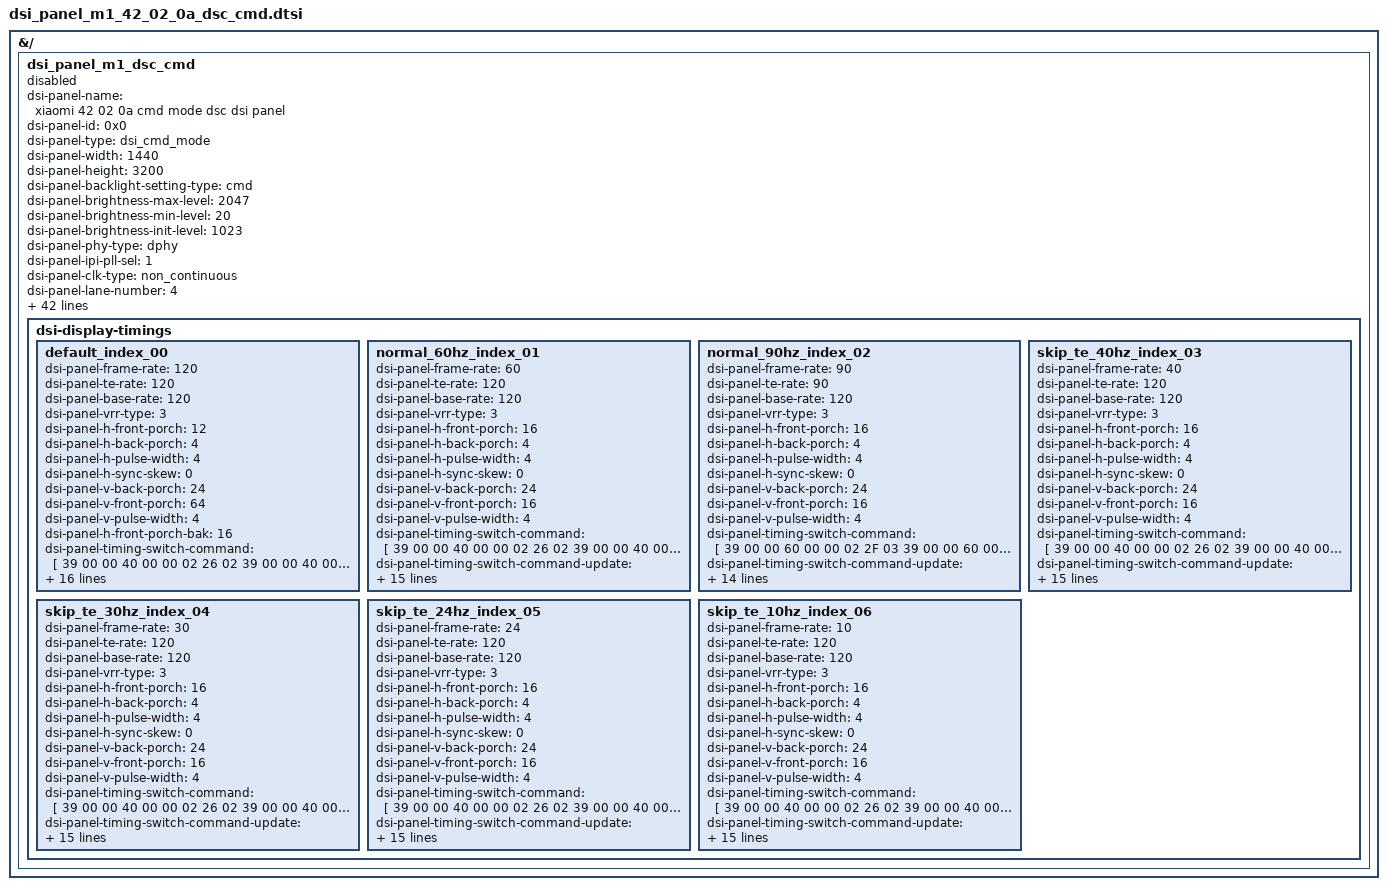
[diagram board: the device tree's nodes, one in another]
// SPDX-License-Identifier: GPL-2.0+
/*
 * DSI panel device tree for fpga testing
 *
 * (C) Copyright 2023 - 2024, X-Ring, Inc.
 */

&{/} {
	dsi_panel_m1_dsc_cmd: dsi_panel_m1_dsc_cmd {
		status = "disabled";
		dsi-panel-name = "xiaomi 42 02 0a cmd mode dsc dsi panel";
		dsi-panel-id = <0x0>;
		dsi-panel-type = "dsi_cmd_mode";
		dsi-panel-width = <1440>;
		dsi-panel-height = <3200>;
		dsi-panel-backlight-setting-type = "cmd";
		dsi-panel-brightness-max-level = <2047>;
		dsi-panel-brightness-min-level = <20>;
		dsi-panel-brightness-init-level = <1023>;
		dsi-panel-phy-type = "dphy";
		dsi-panel-ipi-pll-sel = <1>; // 0:phy pll 1:dpu pll
		dsi-panel-clk-type = "non_continuous";
		dsi-panel-lane-number = <4>;
		dsi-panel-lane-rate = <1360000000>;
		dsi-panel-pixel-clock = <26154000>;
		dsi-panel-lane-rate-bak = <1380924237>;
		dsi-panel-pixel-clock-bak = <26556235>;
		dsi-panel-bpp = <30>;
		dsi-panel-virtual-channel = <0>;
		dsi-panel-bta-enable;
		dsi-panel-eotp-enable;
		dsi-panel-hdr-enabled;
		dsi-panel-peak-brightness = <4200000>;
		dsi-panel-blackness-level = <3230>;
		dsi-panel-physical-width-dimension = <701>;
		dsi-panel-physical-height-dimension = <1558>;
		dsi-panel-physical-type = "ltpo";
		dsi-panel-te-sel = /bits/ 8 <0x0>;
		dsi-panel-port-mask = /bits/ 8 <0x1>; // DSI-0: 0001
		dsi-panel-boot-up-profile = <1>; //profile_1
		dsi-panel-lowpower-ctrl = <0x3fd>; //support frame power ctrl
		dsi-panel-frame-power-mask = <0x6>;
		dsi-panel-frame-power-max-refresh-rate = <30>;
		dsi-panel-hw-ulps-max-refresh-rate = <30>;
		dsi-panel-idle-policy = <0x0>;
		dsi-panel-dsc-compression-mode = "dsc";
		dsi-panel-dsc-version = <0x12>;
		dsi-panel-dsc-scr-version = <0>;
		dsi-panel-dsc-pic-height = <3200>;
		dsi-panel-dsc-pic-width = <1440>;
		dsi-panel-dsc-slice-height = <20>;
		dsi-panel-dsc-slice-width = <720>;
		dsi-panel-dsc-bpc = /bits/ 8 <10>;
		dsi-panel-dsc-bpp = /bits/ 8 <8>;
		dsi-panel-dsc-pps-table = [
			12 00 00 AB 30 80 0C 80 05 A0 00 14 02 D0 02 D0
			02 00 02 86 00 20 02 15 00 0A 00 0D 05 7A 03 D1
			18 00 10 F0 07 10 20 00 06 0F 0F 33 0E 1C 2A 38
			46 54 62 69 70 77 79 7B 7D 7E 02 02 22 00 2A 40
			2A BE 3A FC 3A FA 3A F8 3B 38 3B 78 43 B6 4B B6
			4B F6 4B F4 64 34 84 74 00 00 00 00 00 00 00 00
			00 00 00 00 00 00 00 00 00 00 00 00 00 00 00 00
			00 00 00 00 00 00 00 00 00 00 00 00 00 00 00 00
		];
		dsi-panel-vrr-enable;
		dsi-panel-reset-after-lp11;
		dsi-panel-esd-check-enable;
		dsi-panel-esd-mode = "err_int";
		dsi-panel-status-command = [06 01 00 01 00 00 01 91];
		dsi-panel-status-command-state = "dsi_hs_mode";
		dsi-panel-status-value = <0xAB 0xA8>;
		dsi-panel-status-length = <2>;
		dsi-display-timings {
			default_index_00 {
				dsi-panel-frame-rate = <120>;
				dsi-panel-te-rate = <120>;
				dsi-panel-base-rate = <120>;
				dsi-panel-vrr-type = <3>;
				dsi-panel-h-front-porch = <12>;
				dsi-panel-h-back-porch = <4>;
				dsi-panel-h-pulse-width = <4>;
				dsi-panel-h-sync-skew = <0>;
				dsi-panel-v-back-porch = <24>;
				dsi-panel-v-front-porch = <64>;
				dsi-panel-v-pulse-width = <4>;
				dsi-panel-h-front-porch-bak = <16>;

				dsi-panel-timing-switch-command = [
					/* 120Hz */
					39 00 00 40 00 00 02 26 02
					39 00 00 40 00 00 02 2F 02
					39 00 00 40 00 00 06 F0 55 AA 52 08 00
					39 00 00 40 00 00 02 BC 00
					39 00 00 00 00 00 02 2C 00
				];
				dsi-panel-timing-switch-command-update = <0x26 0 1>, <0x2F 1 1>;
				dsi-panel-timing-switch-command-state = "dsi_hs_mode";
				dsi-panel-flat-mode-gamma-cfg = <0x26 0x00 0x02>, <0x2F 0x00 0x02>;

				dsi-panel-on-command = [
					#include "dsi_panel_m1_42_02_0a_dsc_cmd_dsi_on_common.dtsi"
					/* 120Hz */
					39 00 00 40 00 00 02 26 02
					39 00 00 40 00 00 02 2F 02
					39 00 00 40 00 00 06 F0 55 AA 52 08 00
					39 00 00 40 00 00 02 BC 00
					39 00 00 40 00 00 02 2C 00
					/* Sleep Out */
					05 00 00 00 78 00 01 11
					39 00 00 40 00 00 06 F0 55 AA 52 08 02
					39 00 00 40 00 00 02 CC 10
					/* Display On */
					05 00 00 00 00 00 01 29
				];
				dsi-panel-on-command-state = "dsi_hs_mode";

				dsi-panel-off-command = [
					/*AOD Off*/
					39 00 00 40 00 00 02 65 00
					39 00 00 40 00 00 02 38 00
					39 00 00 00 32 00 02 2C 00
					/*Power off*/
					05 00 00 00 00 00 01 28
					05 00 00 00 78 00 01 10
				];
				dsi-panel-off-command-state = "dsi_hs_mode";

				dsi-panel-backlight-command = [
					39 00 00 00 00 00 03 51 03 FF
				];
				dsi-panel-backlight-command-update = <0x51 0 2>;
				dsi-panel-backlight-command-state = "dsi_hs_mode";
			};
			normal_60hz_index_01 {
				dsi-panel-frame-rate = <60>;
				dsi-panel-te-rate = <120>;
				dsi-panel-base-rate = <120>;
				dsi-panel-vrr-type = <3>;
				dsi-panel-h-front-porch = <16>;
				dsi-panel-h-back-porch = <4>;
				dsi-panel-h-pulse-width = <4>;
				dsi-panel-h-sync-skew = <0>;
				dsi-panel-v-back-porch = <24>;
				dsi-panel-v-front-porch = <16>;
				dsi-panel-v-pulse-width = <4>;

				dsi-panel-timing-switch-command = [
					/* 120Hz */
					39 00 00 40 00 00 02 26 02
					39 00 00 40 00 00 02 2F 02
					39 00 00 40 00 00 06 F0 55 AA 52 08 00
					39 00 00 40 00 00 02 BC 00
					39 00 00 00 00 00 02 2C 00
				];
				dsi-panel-timing-switch-command-update = <0x26 0 1>, <0x2F 1 1>;
				dsi-panel-timing-switch-command-state = "dsi_hs_mode";
				dsi-panel-flat-mode-gamma-cfg = <0x26 0x00 0x02>, <0x2F 0x00 0x02>;

				dsi-panel-on-command = [
					#include "dsi_panel_m1_42_02_0a_dsc_cmd_dsi_on_common.dtsi"
					/* 120Hz */
					39 00 00 40 00 00 02 26 02
					39 00 00 40 00 00 02 2F 02
					39 00 00 40 00 00 06 F0 55 AA 52 08 00
					39 00 00 40 00 00 02 BC 00
					39 00 00 40 00 00 02 2C 00
					/* Sleep Out */
					05 00 00 00 78 00 01 11
					39 00 00 40 00 00 06 F0 55 AA 52 08 02
					39 00 00 40 00 00 02 CC 10
					/* Display On */
					05 00 00 00 00 00 01 29
				];
				dsi-panel-on-command-state = "dsi_hs_mode";

				dsi-panel-off-command = [
					/*AOD Off*/
					39 00 00 40 00 00 02 65 00
					39 00 00 40 00 00 02 38 00
					39 00 00 00 32 00 02 2C 00
					/*Power off*/
					05 00 00 00 00 00 01 28
					05 00 00 00 78 00 01 10
				];
				dsi-panel-off-command-state = "dsi_hs_mode";

				dsi-panel-backlight-command = [
					39 00 00 00 00 00 03 51 03 FF
				];
				dsi-panel-backlight-command-update = <0x51 0 2>;
				dsi-panel-backlight-command-state = "dsi_hs_mode";
			};
			normal_90hz_index_02 {
				dsi-panel-frame-rate = <90>;
				dsi-panel-te-rate = <90>;
				dsi-panel-base-rate = <120>;
				dsi-panel-vrr-type = <3>;
				dsi-panel-h-front-porch = <16>;
				dsi-panel-h-back-porch = <4>;
				dsi-panel-h-pulse-width = <4>;
				dsi-panel-h-sync-skew = <0>;
				dsi-panel-v-back-porch = <24>;
				dsi-panel-v-front-porch = <16>;
				dsi-panel-v-pulse-width = <4>;

				dsi-panel-timing-switch-command = [
					39 00 00 60 00 00 02 2F 03
					39 00 00 60 00 00 06 F0 55 AA 52 08 00
					39 00 00 20 00 00 02 BC 00
				];
				dsi-panel-timing-switch-command-update = <0x2F 0 1>;
				dsi-panel-timing-switch-command-state = "dsi_hs_mode";
				dsi-panel-flat-mode-gamma-cfg = <0x2F 0x01 0x03>;

				dsi-panel-on-command = [
					#include "dsi_panel_m1_42_02_0a_dsc_cmd_dsi_on_common.dtsi"
					/* 90HZ */
					39 00 00 40 00 00 02 2F 03
					39 00 00 40 00 00 06 F0 55 AA 52 08 00
					39 00 00 40 00 00 02 BC 00
					/* Sleep Out */
					05 00 00 00 78 00 01 11
					39 00 00 40 00 00 06 F0 55 AA 52 08 02
					39 00 00 40 00 00 02 CC 10
					/* Display On */
					05 00 00 00 00 00 01 29
				];
				dsi-panel-on-command-state = "dsi_hs_mode";

				dsi-panel-off-command = [
					/*AOD Off*/
					39 00 00 40 00 00 02 65 00
					39 00 00 40 00 00 02 38 00
					39 00 00 00 32 00 02 2C 00
					/*Power off*/
					05 00 00 00 00 00 01 28
					05 00 00 00 78 00 01 10
				];
				dsi-panel-off-command-state = "dsi_hs_mode";

				dsi-panel-backlight-command = [
					39 00 00 00 00 00 03 51 03 FF
				];
				dsi-panel-backlight-command-update = <0x51 0 2>;
				dsi-panel-backlight-command-state = "dsi_hs_mode";
			};
			skip_te_40hz_index_03 {
				dsi-panel-frame-rate = <40>;
				dsi-panel-te-rate = <120>;
				dsi-panel-base-rate = <120>;
				dsi-panel-vrr-type = <3>;
				dsi-panel-h-front-porch = <16>;
				dsi-panel-h-back-porch = <4>;
				dsi-panel-h-pulse-width = <4>;
				dsi-panel-h-sync-skew = <0>;
				dsi-panel-v-back-porch = <24>;
				dsi-panel-v-front-porch = <16>;
				dsi-panel-v-pulse-width = <4>;

				dsi-panel-timing-switch-command = [
					/* 120Hz */
					39 00 00 40 00 00 02 26 02
					39 00 00 40 00 00 02 2F 02
					39 00 00 40 00 00 06 F0 55 AA 52 08 00
					39 00 00 40 00 00 02 BC 00
					39 00 00 00 00 00 02 2C 00
				];
				dsi-panel-timing-switch-command-update = <0x26 0 1>, <0x2F 1 1>;
				dsi-panel-timing-switch-command-state = "dsi_hs_mode";
				dsi-panel-flat-mode-gamma-cfg = <0x26 0x00 0x02>, <0x2F 0x00 0x02>;

				dsi-panel-on-command = [
					#include "dsi_panel_m1_42_02_0a_dsc_cmd_dsi_on_common.dtsi"
					/* 120Hz */
					39 00 00 40 00 00 02 26 02
					39 00 00 40 00 00 02 2F 02
					39 00 00 40 00 00 06 F0 55 AA 52 08 00
					39 00 00 40 00 00 02 BC 00
					39 00 00 40 00 00 02 2C 00
					/* Sleep Out */
					05 00 00 00 78 00 01 11
					39 00 00 40 00 00 06 F0 55 AA 52 08 02
					39 00 00 40 00 00 02 CC 10
					/* Display On */
					05 00 00 00 00 00 01 29
				];
				dsi-panel-on-command-state = "dsi_hs_mode";

				dsi-panel-off-command = [
					/*AOD Off*/
					39 00 00 40 00 00 02 65 00
					39 00 00 40 00 00 02 38 00
					39 00 00 00 32 00 02 2C 00
					/*Power off*/
					05 00 00 00 00 00 01 28
					05 00 00 00 78 00 01 10
				];
				dsi-panel-off-command-state = "dsi_hs_mode";

				dsi-panel-backlight-command = [
					39 00 00 00 00 00 03 51 03 FF
				];
				dsi-panel-backlight-command-update = <0x51 0 2>;
				dsi-panel-backlight-command-state = "dsi_hs_mode";
			};
			skip_te_30hz_index_04 {
				dsi-panel-frame-rate = <30>;
				dsi-panel-te-rate = <120>;
				dsi-panel-base-rate = <120>;
				dsi-panel-vrr-type = <3>;
				dsi-panel-h-front-porch = <16>;
				dsi-panel-h-back-porch = <4>;
				dsi-panel-h-pulse-width = <4>;
				dsi-panel-h-sync-skew = <0>;
				dsi-panel-v-back-porch = <24>;
				dsi-panel-v-front-porch = <16>;
				dsi-panel-v-pulse-width = <4>;

				dsi-panel-timing-switch-command = [
					/* 120Hz */
					39 00 00 40 00 00 02 26 02
					39 00 00 40 00 00 02 2F 02
					39 00 00 40 00 00 06 F0 55 AA 52 08 00
					39 00 00 40 00 00 02 BC 00
					39 00 00 00 00 00 02 2C 00
				];
				dsi-panel-timing-switch-command-update = <0x26 0 1>, <0x2F 1 1>;
				dsi-panel-timing-switch-command-state = "dsi_hs_mode";
				dsi-panel-flat-mode-gamma-cfg = <0x26 0x00 0x02>, <0x2F 0x00 0x02>;

				dsi-panel-on-command = [
					#include "dsi_panel_m1_42_02_0a_dsc_cmd_dsi_on_common.dtsi"
					/* 120Hz */
					39 00 00 40 00 00 02 26 02
					39 00 00 40 00 00 02 2F 02
					39 00 00 40 00 00 06 F0 55 AA 52 08 00
					39 00 00 40 00 00 02 BC 00
					39 00 00 40 00 00 02 2C 00
					/* Sleep Out */
					05 00 00 00 78 00 01 11
					39 00 00 40 00 00 06 F0 55 AA 52 08 02
					39 00 00 40 00 00 02 CC 10
					/* Display On */
					05 00 00 00 00 00 01 29
				];
				dsi-panel-on-command-state = "dsi_hs_mode";

				dsi-panel-off-command = [
					/*AOD Off*/
					39 00 00 40 00 00 02 65 00
					39 00 00 40 00 00 02 38 00
					39 00 00 00 32 00 02 2C 00
					/*Power off*/
					05 00 00 00 00 00 01 28
					05 00 00 00 78 00 01 10
				];
				dsi-panel-off-command-state = "dsi_hs_mode";

				dsi-panel-backlight-command = [
					39 00 00 00 00 00 03 51 03 FF
				];
				dsi-panel-backlight-command-update = <0x51 0 2>;
				dsi-panel-backlight-command-state = "dsi_hs_mode";
			};
			skip_te_24hz_index_05 {
				dsi-panel-frame-rate = <24>;
				dsi-panel-te-rate = <120>;
				dsi-panel-base-rate = <120>;
				dsi-panel-vrr-type = <3>;
				dsi-panel-h-front-porch = <16>;
				dsi-panel-h-back-porch = <4>;
				dsi-panel-h-pulse-width = <4>;
				dsi-panel-h-sync-skew = <0>;
				dsi-panel-v-back-porch = <24>;
				dsi-panel-v-front-porch = <16>;
				dsi-panel-v-pulse-width = <4>;

				dsi-panel-timing-switch-command = [
					/* 120Hz */
					39 00 00 40 00 00 02 26 02
					39 00 00 40 00 00 02 2F 02
					39 00 00 40 00 00 06 F0 55 AA 52 08 00
					39 00 00 40 00 00 02 BC 00
					39 00 00 00 00 00 02 2C 00
				];
				dsi-panel-timing-switch-command-update = <0x26 0 1>, <0x2F 1 1>;
				dsi-panel-timing-switch-command-state = "dsi_hs_mode";
				dsi-panel-flat-mode-gamma-cfg = <0x26 0x00 0x02>, <0x2F 0x00 0x02>;

				dsi-panel-on-command = [
					#include "dsi_panel_m1_42_02_0a_dsc_cmd_dsi_on_common.dtsi"
					/* 120Hz */
					39 00 00 40 00 00 02 26 02
					39 00 00 40 00 00 02 2F 02
					39 00 00 40 00 00 06 F0 55 AA 52 08 00
					39 00 00 40 00 00 02 BC 00
					39 00 00 40 00 00 02 2C 00
					/* Sleep Out */
					05 00 00 00 78 00 01 11
					39 00 00 40 00 00 06 F0 55 AA 52 08 02
					39 00 00 40 00 00 02 CC 10
					/* Display On */
					05 00 00 00 00 00 01 29
				];
				dsi-panel-on-command-state = "dsi_hs_mode";

				dsi-panel-off-command = [
					/*AOD Off*/
					39 00 00 40 00 00 02 65 00
					39 00 00 40 00 00 02 38 00
					39 00 00 00 32 00 02 2C 00
					/*Power off*/
					05 00 00 00 00 00 01 28
					05 00 00 00 78 00 01 10
				];
				dsi-panel-off-command-state = "dsi_hs_mode";

				dsi-panel-backlight-command = [
					39 00 00 00 00 00 03 51 03 FF
				];
				dsi-panel-backlight-command-update = <0x51 0 2>;
				dsi-panel-backlight-command-state = "dsi_hs_mode";
			};
			skip_te_10hz_index_06 {
				dsi-panel-frame-rate = <10>;
				dsi-panel-te-rate = <120>;
				dsi-panel-base-rate = <120>;
				dsi-panel-vrr-type = <3>;
				dsi-panel-h-front-porch = <16>;
				dsi-panel-h-back-porch = <4>;
				dsi-panel-h-pulse-width = <4>;
				dsi-panel-h-sync-skew = <0>;
				dsi-panel-v-back-porch = <24>;
				dsi-panel-v-front-porch = <16>;
				dsi-panel-v-pulse-width = <4>;

				dsi-panel-timing-switch-command = [
					/* 120Hz */
					39 00 00 40 00 00 02 26 02
					39 00 00 40 00 00 02 2F 02
					39 00 00 40 00 00 06 F0 55 AA 52 08 00
					39 00 00 40 00 00 02 BC 00
					39 00 00 00 00 00 02 2C 00
				];
				dsi-panel-timing-switch-command-update = <0x26 0 1>, <0x2F 1 1>;
				dsi-panel-timing-switch-command-state = "dsi_hs_mode";
				dsi-panel-flat-mode-gamma-cfg = <0x26 0x00 0x02>, <0x2F 0x00 0x02>;

				dsi-panel-on-command = [
					#include "dsi_panel_m1_42_02_0a_dsc_cmd_dsi_on_common.dtsi"
					/* 120Hz */
					39 00 00 40 00 00 02 26 02
					39 00 00 40 00 00 02 2F 02
					39 00 00 40 00 00 06 F0 55 AA 52 08 00
					39 00 00 40 00 00 02 BC 00
					39 00 00 40 00 00 02 2C 00
					/* Sleep Out */
					05 00 00 00 78 00 01 11
					39 00 00 40 00 00 06 F0 55 AA 52 08 02
					39 00 00 40 00 00 02 CC 10
					/* Display On */
					05 00 00 00 00 00 01 29
				];
				dsi-panel-on-command-state = "dsi_hs_mode";

				dsi-panel-off-command = [
					/*AOD Off*/
					39 00 00 40 00 00 02 65 00
					39 00 00 40 00 00 02 38 00
					39 00 00 00 32 00 02 2C 00
					/*Power off*/
					05 00 00 00 00 00 01 28
					05 00 00 00 78 00 01 10
				];
				dsi-panel-off-command-state = "dsi_hs_mode";

				dsi-panel-backlight-command = [
					39 00 00 00 00 00 03 51 03 FF
				];
				dsi-panel-backlight-command-update = <0x51 0 2>;
				dsi-panel-backlight-command-state = "dsi_hs_mode";
			};
		};
	};
};
